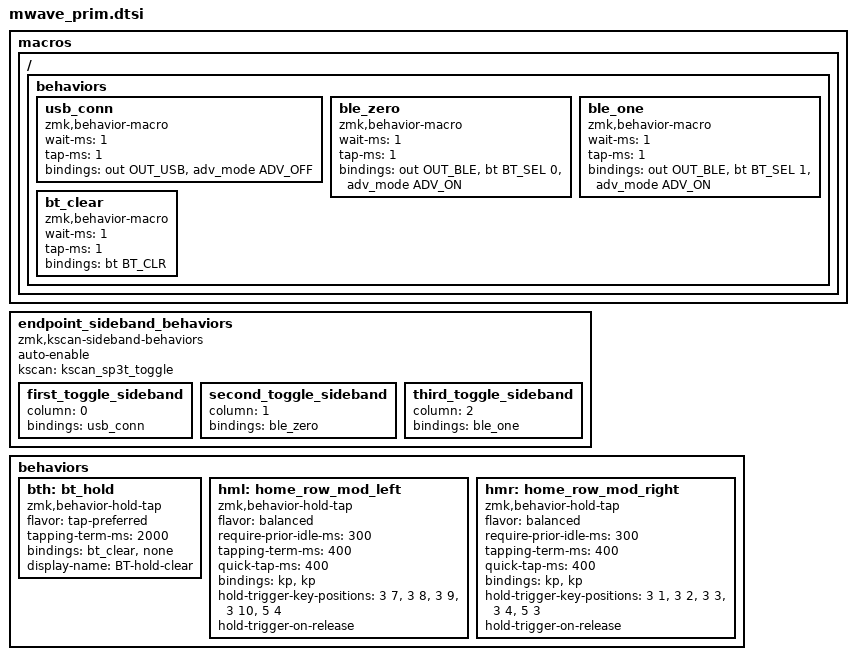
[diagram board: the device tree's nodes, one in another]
macros {
    ZMK_MACRO(usb_conn,
        wait-ms = <1>;
        tap-ms = <1>;
        bindings = <&out OUT_USB &adv_mode ADV_OFF>;
    )
    ZMK_MACRO(ble_zero,
        wait-ms = <1>;
        tap-ms = <1>;
        bindings = <&out OUT_BLE &bt BT_SEL 0 &adv_mode ADV_ON>;
    )
    ZMK_MACRO(ble_one,
        wait-ms = <1>;
        tap-ms = <1>;
        bindings = <&out OUT_BLE &bt BT_SEL 1 &adv_mode ADV_ON>;
    )
    ZMK_MACRO(bt_clear,
        wait-ms = <1>;
        tap-ms = <1>;
        bindings = <&bt BT_CLR>;
    )
    #include "version.dtsi"
};

endpoint_sideband_behaviors {
    auto-enable;
    compatible = "zmk,kscan-sideband-behaviors";
    kscan = <&kscan_sp3t_toggle>;

    first_toggle_sideband: first_toggle_sideband {
        column = <0>;
        bindings = <&usb_conn>;
    };

    second_toggle_sideband: second_toggle_sideband {
        column = <1>;
        bindings = <&ble_zero>;
    };

    third_toggle_sideband: third_toggle_sideband {
        column = <2>;
        bindings = <&ble_one>;
    };
};

behaviors {
    bth: bt_hold {
        compatible = "zmk,behavior-hold-tap";
        #binding-cells = <2>;
        flavor = "tap-preferred";
        tapping-term-ms = <2000>;
        bindings = <&bt_clear>, <&none>;
        display-name = "BT-hold-clear";
    };
    hml: home_row_mod_left {
        compatible = "zmk,behavior-hold-tap";
        #binding-cells = <2>;
        flavor = "balanced";
        require-prior-idle-ms = <300>;
        tapping-term-ms = <400>;
        quick-tap-ms = <400>;
        bindings = <&kp>, <&kp>;
        hold-trigger-key-positions = <3 7>, <3 8>, <3 9>, <3 10>, <5 4>; // List of keys on the right side of the keyboard
        hold-trigger-on-release;
    };
    hmr: home_row_mod_right {
        compatible = "zmk,behavior-hold-tap";
        #binding-cells = <2>;
        flavor = "balanced";
        require-prior-idle-ms = <300>;
        tapping-term-ms = <400>;
        quick-tap-ms = <400>;
        bindings = <&kp>, <&kp>;
        hold-trigger-key-positions = <3 1>, <3 2>, <3 3>, <3 4>, <5 3>; // List of keys on the left side of the keyboard
        hold-trigger-on-release;
    };
};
